# STM32WBA24 register map
File version: 0.2
CPU: CM33 r0p1, little endian, MPU, FPU, 4 interrupt priority bits
Registers are 32-bit, read-write, reset 0x0 unless marked. A register's access mark holds for its fields unless they carry their own. Offsets are from the block's base; [hi:lo] are bit positions; {n}, {i} and the like mark numbered series.

## ICACHE — ICACHE register block
Base 0x40030400
Same registers: SEC_ICACHE 0x50030400
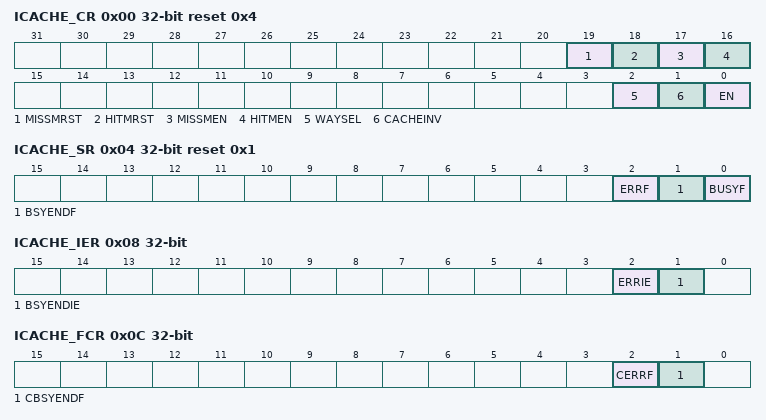
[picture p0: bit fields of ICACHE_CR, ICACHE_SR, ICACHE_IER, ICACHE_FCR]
0x00 ICACHE_CR reset 0x4 — ICACHE control register
  [19] MISSMRST — miss monitor reset
    0=release the cache miss monitor reset (needed to enable the counting); 1=reset cache miss monitor
  [18] HITMRST — hit monitor reset
    0=release the cache miss monitor reset (needed to enable the counting); 1=reset cache hit monitor
  [17] MISSMEN — miss monitor enable
    0=cache miss monitor switched off; 1=cache miss monitor enabled
  [16] HITMEN — hit monitor enable
    0=cache hit monitor switched off; 1=cache hit monitor enabled
  [2] WAYSEL — cache associativity mode selection
    0=direct mapped cache (1-way cache); 1=n-way set associative cache (reset value)
  [1] CACHEINV wo — cache invalidation
    0=no effect; 1=invalidate entire cache (all cache lines valid bit = 0)
  [0] EN — enable
    0=cache disabled; 1=cache enabled
0x04 ICACHE_SR ro reset 0x1 — ICACHE status register
  [2] ERRF — cache error flag
    0=no error; 1=an error occurred during the operation (cacheable write)
  [1] BSYENDF — busy end flag
    0=cache busy; 1=full invalidate CACHEINV operation finished
  [0] BUSYF — busy flag
    0=cache not busy on a CACHEINV operation; 1=cache executing a full invalidate CACHEINV operation
0x08 ICACHE_IER — ICACHE interrupt enable register
  [2] ERRIE — interrupt enable on cache error
    0=interrupt disabled on error; 1=interrupt enabled on error
  [1] BSYENDIE — interrupt enable on busy end
    0=interrupt disabled on busy end; 1=interrupt enabled on busy end
0x0C ICACHE_FCR wo — ICACHE flag clear register
  [2] CERRF — clear cache error flag
    0=no effect; 1=clears ERRF flag in ICACHE_SR
  [1] CBSYENDF — clear busy end flag
    0=no effect; 1=clears BSYENDF flag in ICACHE_SR
0x10 ICACHE_HMONR ro — ICACHE hit monitor register
  [31:0] HITMON — cache hit monitor counter
0x14 ICACHE_MMONR ro — ICACHE miss monitor register
  [15:0] MISSMON — cache miss monitor counter
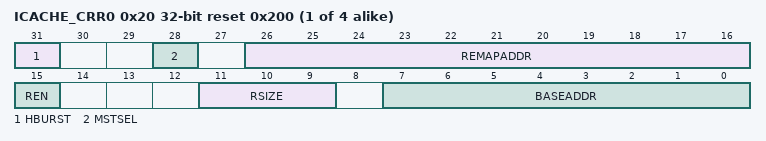
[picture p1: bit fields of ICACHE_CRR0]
{0x20+4i} ICACHE_CRR{i} reset 0x200 (i=0..3) — ICACHE region {i} configuration register
  [31] HBURST — output burst type for region x
    0=WRAP; 1=INCR
  [28] MSTSEL — AHB cache master selection for region x
    0=no action (master1 selected by default); 1=master2 selected
  [26:16] REMAPADDR — remapped address for region x
  [15] REN — enable for region x
    0=disabled; 1=enabled
  [11:9] RSIZE — size for region x
    1=2 Mbytes; 2=4 Mbytes; 3=8 Mbytes; 4=16 Mbytes; 5=32 Mbytes; 6=64 Mbytes; 7=128 Mbytes
  [7:0] BASEADDR — base address for region x

## PTACONV — PTACONV register block
Base 0x48038000
Same registers: SEC_PTACONV 0x58038000
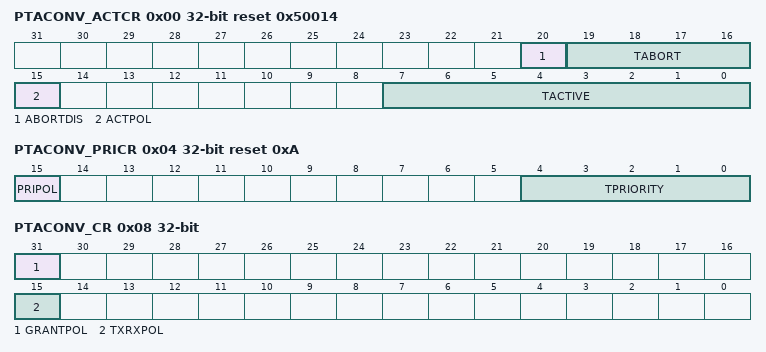
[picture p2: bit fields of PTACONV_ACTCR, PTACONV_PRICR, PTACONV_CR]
0x00 PTACONV_ACTCR reset 0x50014 — PTACONV active control register
  [20] ABORTDIS — Disable PTA_ACTIVE deny to abort an ongoing transmission
    0=PTA_ACTIVE deny aborts an ongoing transmission; 1=PTA_ACTIVE deny does not abort an ongoing transmission
  [19:16] TABORT — PTA_ACTIVE delay to cease an ongoing transmission in us
  [15] ACTPOL — PTA_ACTIVE polarity
    0=PTA_ACTIVE active high; 1=PTA_ACTIVE active low
  [7:0] TACTIVE — PTA_ACTIVE setup time in us
0x04 PTACONV_PRICR reset 0xA — PTACONV priority control register
  [15] PRIPOL — Priority polarity
    0=priority on PTA_PRIORITY or PTA_STATUS not inverted; 1=inverted priority on PTA_PRIORITY or PTA_STATUS
  [4:0] TPRIORITY — Priority valid time in us
    0=no time-multiplexed priority information on PTA_STATUS
0x08 PTACONV_CR — PTACONV control register
  [31] GRANTPOL — PTA_GRANT polarity
    0=PTA_GRANT active low; 1=PTA_GRANT active high
  [15] TXRXPOL — PTA_STATUS transmit and receive polarity
    0=PTA_STATUS receive = 0, transmit = 1; 1=PTA_STATUS receive = 1, transmit = 0
